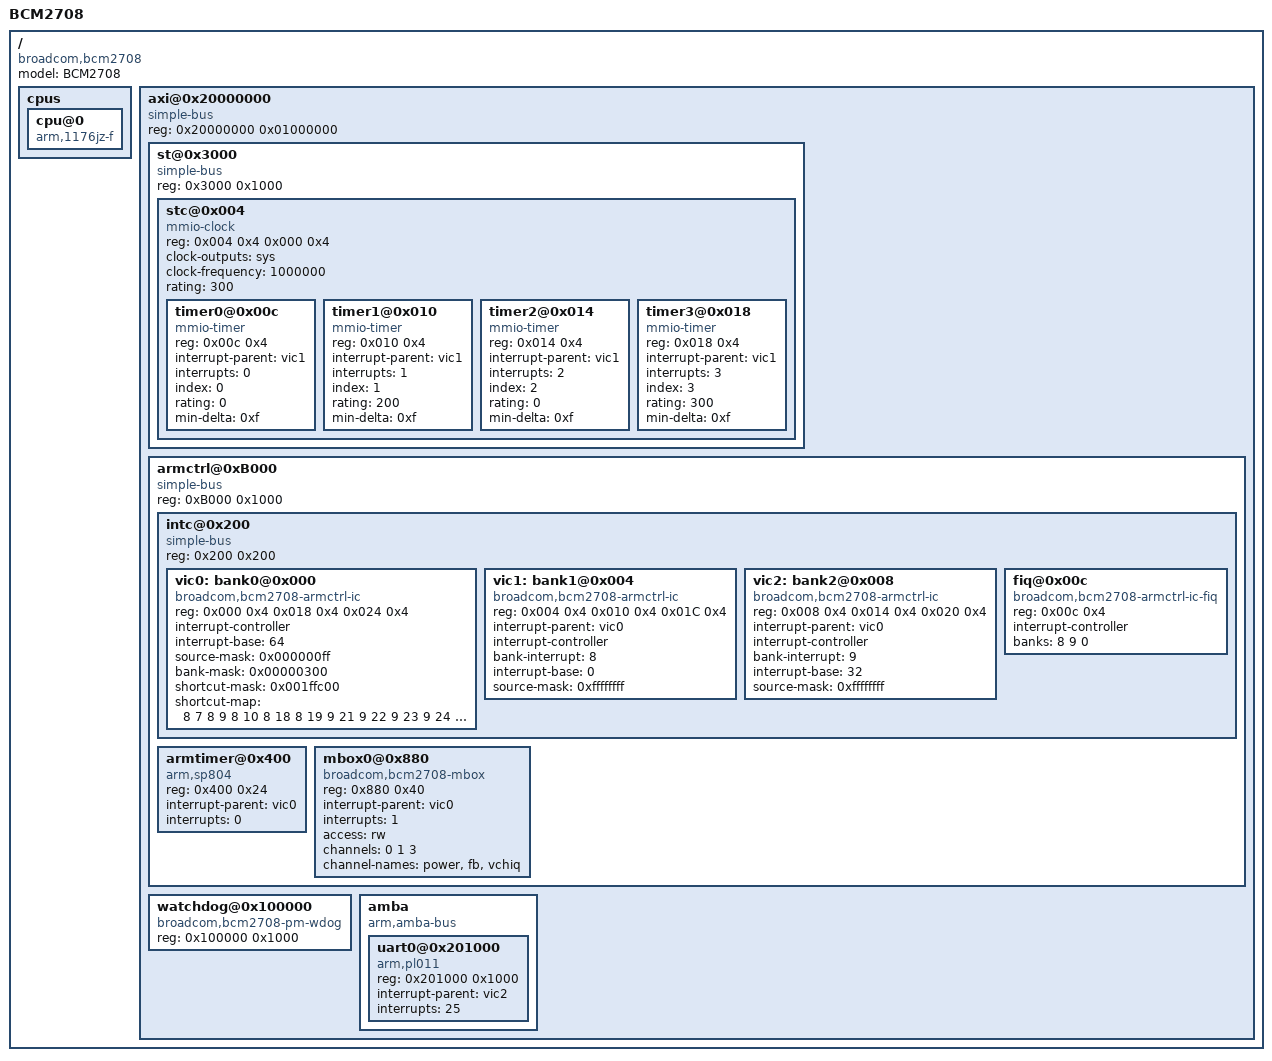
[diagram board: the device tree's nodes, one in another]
/dts-v1/;
/include/ "skeleton.dtsi"

/ {
	model = "BCM2708";
	#address-cells = <1>;
	#size-cells = <1>;
	compatible = "broadcom,bcm2708";

	cpus {
		cpu@0 {
			compatible = "arm,1176jz-f";
		};
	};

	axi@0x20000000 {
		compatible = "simple-bus";
		#address-cells = <1>;
		#size-cells = <1>;
		reg = <0x20000000 0x01000000>;
		ranges = <0 0x20000000 0x01000000>;


		st@0x3000 {
			compatible = "simple-bus";
			#address-cells = <1>;
			#size-cells = <1>;
			reg = <0x3000 0x1000>;
			ranges = <0 0x3000 0x1000>;

			stc@0x004 {
				compatible = "mmio-clock", "simple-bus";
				#address-cells = <1>;
				#size-cells = <1>;
				reg = <0x004 0x4 0x000 0x4>;
				ranges;

				clock-outputs = "sys";
				clock-frequency = <1000000>;
				rating = <300>;

				/* DO NOT USE (it doesn't work) */
				timer0@0x00c {
					compatible = "mmio-timer";
					reg = <0x00c 0x4>;
					interrupt-parent = <&vic1>;
					interrupts = <0>;

					index = <0>;
					rating = <0>;
					min-delta = <0xf>;
				};

				/* Usable system timer */
				timer1@0x010 {
					compatible = "mmio-timer";
					reg = <0x010 0x4>;
					interrupt-parent = <&vic1>;
					interrupts = <1>;

					index = <1>;
					rating = <200>;
					min-delta = <0xf>;
				};

				/* DO NOT USE (generates extra interrupts) */
				timer2@0x014 {
					compatible = "mmio-timer";
					reg = <0x014 0x4>;
					interrupt-parent = <&vic1>;
					interrupts = <2>;

					index = <2>;
					rating = <0>;
					min-delta = <0xf>;
				};

				/* Usable system timer */
				timer3@0x018 {
					compatible = "mmio-timer";
					reg = <0x018 0x4>;
					interrupt-parent = <&vic1>;
					interrupts = <3>;

					index = <3>;
					rating = <300>;
					min-delta = <0xf>;
				};
			};
		};

		armctrl@0xB000 {
			compatible = "simple-bus";
			#address-cells = <1>;
			#size-cells = <1>;
			reg = <0xB000 0x1000>;
			ranges = <0 0xB000 0x1000>;

			intc@0x200 {
				compatible = "simple-bus";
				#address-cells = <1>;
				#size-cells = <1>;
				reg = <0x200 0x200>;
				ranges = <0 0x200 0x200>;

				vic0: bank0@0x000 {
					compatible = "broadcom,bcm2708-armctrl-ic";
					reg = <0x000 0x4 0x018 0x4 0x024 0x4>;
					interrupt-controller;
					#interrupt-cells = <1>;

					interrupt-base = <64>;

					/* IRQs
					 * 0: ARM_TIMER
					 * 1: ARM_MAILBOX
					 * 2: ARM_DOORBELL_0
					 * 3: ARM_DOORBELL_1
					 * 4: VPU0_HALTED
					 * 5: VPU1_HALTED
					 * 6: ILLEGAL_TYPE0
					 * 7: ILLEGAL_TYPE1
					 */
					source-mask = <0x000000ff>;

					/* Banks
					 * 8: PENDING1
					 * 9: PENDING2
					 */
					bank-mask = <0x00000300>;

					/* Shortcuts */
					shortcut-mask = <0x001ffc00>;
					shortcut-map = <
						8  7	/* 10: VC_JPEG */
						8  9	/* 11: VC_USB */
						8 10	/* 12: VC_3D */
						8 18	/* 13: VC_DMA2 */
						8 19	/* 14: VC_DMA3 */
						9 21	/* 15: VC_I2C */
						9 22	/* 16: VC_SPI */
						9 23	/* 17: VC_I2SPCM */
						9 24	/* 18: VC_SDIO */
						9 25	/* 19: VC_UART */
						9 30	/* 20: VC_ARASANSDIO */
					>;
				};

				vic1: bank1@0x004 {
					compatible = "broadcom,bcm2708-armctrl-ic";
					reg = <0x004 0x4 0x010 0x4 0x01C 0x4>;
					interrupt-parent = <&vic0>;
					interrupt-controller;
					#interrupt-cells = <1>;
					#address-cells = <0>;

					bank-interrupt = <8>;
					interrupt-base = <0>;

					/* IRQs
					 * 0: TIMER0		16: DMA0
					 * 1: TIMER1		17: DMA1
					 * 2: TIMER2		18: VC_DMA2
					 * 3: TIMER3		19: VC_DMA3
					 * 4: CODEC0		20: DMA4
					 * 5: CODEC1		21: DMA5
					 * 6: CODEC2		22: DMA6
					 * 7: VC_JPEG		23: DMA7
					 * 8: ISP		24: DMA8
					 * 9: VC_USB		25: DMA9
					 * 10: VC_3D		26: DMA10
					 * 11: TRANSPOSER	27: DMA11
					 * 12: MULTICORESYNC0	28: DMA12
					 * 13: MULTICORESYNC1	29: AUX
					 * 14: MULTICORESYNC2	30: ARM
					 * 15: MULTICORESYNC3	31: VPUDMA
					 */
					source-mask = <0xffffffff>;
				};

				vic2: bank2@0x008 {
					compatible = "broadcom,bcm2708-armctrl-ic";
					reg = <0x008 0x4 0x014 0x4 0x020 0x4>;
					interrupt-parent = <&vic0>;
					interrupt-controller;
					#interrupt-cells = <1>;
					#address-cells = <0>;

					bank-interrupt = <9>;
					interrupt-base = <32>;

					/* IRQs
					 * 0: HOSTPORT		16: SMI
					 * 1: VIDEOSCALER	17: GPIO0
					 * 2: CCP2TX		18: GPIO1
					 * 3: SDC		19: GPIO2
					 * 4: DSI0		20: GPIO3
					 * 5: AVE		21: VC_I2C
					 * 6: CAM0		22: VC_SPI
					 * 7: CAM1		23: VC_I2SPCM
					 * 8: HDMI0		24: VC_SDIO
					 * 9: HDMI1		25: VC_UART
					 * 10: PIXELVALVE1	26: SLIMBUS
					 * 11: I2CSPISLV	27: VEC
					 * 12: DSI1		28: CPG
					 * 13: PWA0		29: RNG
					 * 14: PWA1		30: VC_ARASANSDIO
					 * 15: CPR		31: AVSPMON
					 */
					source-mask = <0xffffffff>;
				};

				fiq@0x00c {
					compatible = "broadcom,bcm2708-armctrl-ic-fiq";
					reg = <0x00c 0x4>;
					interrupt-controller;
					#interrupt-cells = <0>;

					banks = <8 9 0>;
				};
			};

			armtimer@0x400 {
				/* Not AMBA compatible */
				compatible = "arm,sp804";
				reg = <0x400 0x24>;

				interrupt-parent = <&vic0>;
				interrupts = <0>;
			};

			mbox0@0x880 {
				compatible = "broadcom,bcm2708-mbox";
				reg = <0x880 0x40>;
				interrupt-parent = <&vic0>;
				interrupts = <1>;

				/* Read from 0x00..0x1f, Write to 0x20..3f */
				access = "rw";
				channels = <0 1 3>;
				channel-names = "power", "fb", "vchiq";
			};
		};

		watchdog@0x100000 {
			compatible = "broadcom,bcm2708-pm-wdog";
			reg = <0x100000 0x1000>;
		};

		amba {
			compatible = "arm,amba-bus";
			#address-cells = <1>;
			#size-cells = <1>;
			ranges;

			uart0@0x201000 {
				compatible = "arm,pl011", "arm,primecell";
				reg = <0x201000 0x1000>;
				interrupt-parent = <&vic2>;
				interrupts = <25>;
			};
		};

		/* Auxiliary device disabled by default */
		/*
		uart1@0x215000 {
			compatible = "ns16550";
			reg = <0x215040 0x38>;
			interrupt-parent = <&vic1>;
			interrupts = <29>;
		};
		*/
	};
};
